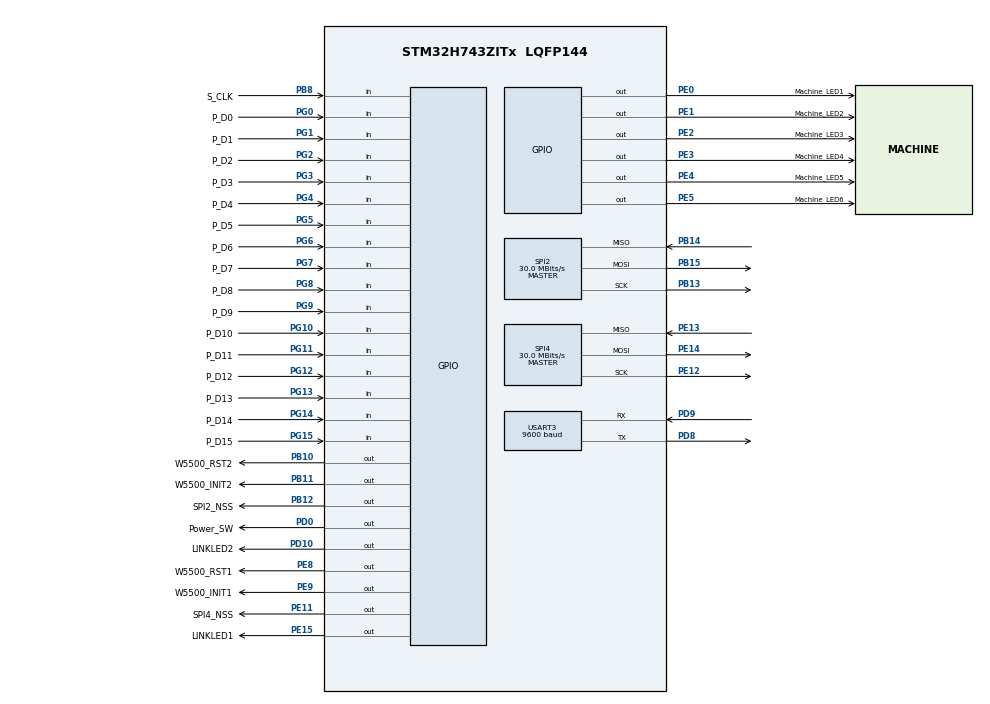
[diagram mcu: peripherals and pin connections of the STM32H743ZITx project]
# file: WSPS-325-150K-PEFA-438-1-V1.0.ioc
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Dma.Request0=USART3_RX
Dma.Request1=USART3_TX
Dma.USART3_RX.0.Direction=DMA_PERIPH_TO_MEMORY
Dma.USART3_RX.0.EventEnable=DISABLE
Dma.USART3_RX.0.FIFOMode=DMA_FIFOMODE_DISABLE
Dma.USART3_RX.0.Instance=DMA1_Stream0
Dma.USART3_RX.0.MemDataAlignment=DMA_MDATAALIGN_BYTE
Dma.USART3_RX.0.MemInc=DMA_MINC_ENABLE
Dma.USART3_RX.0.Mode=DMA_NORMAL
Dma.USART3_RX.0.PeriphDataAlignment=DMA_PDATAALIGN_BYTE
Dma.USART3_RX.0.PeriphInc=DMA_PINC_DISABLE
Dma.USART3_RX.0.Polarity=HAL_DMAMUX_REQ_GEN_RISING
Dma.USART3_RX.0.Priority=DMA_PRIORITY_LOW
Dma.USART3_RX.0.RequestNumber=1
Dma.USART3_RX.0.SignalID=NONE
Dma.USART3_RX.0.SyncEnable=DISABLE
Dma.USART3_RX.0.SyncPolarity=HAL_DMAMUX_SYNC_NO_EVENT
Dma.USART3_RX.0.SyncRequestNumber=1
Dma.USART3_RX.0.SyncSignalID=NONE
Dma.USART3_TX.1.Direction=DMA_MEMORY_TO_PERIPH
Dma.USART3_TX.1.EventEnable=DISABLE
Dma.USART3_TX.1.FIFOMode=DMA_FIFOMODE_DISABLE
Dma.USART3_TX.1.Instance=DMA1_Stream1
Dma.USART3_TX.1.MemDataAlignment=DMA_MDATAALIGN_BYTE
Dma.USART3_TX.1.MemInc=DMA_MINC_ENABLE
Dma.USART3_TX.1.Mode=DMA_NORMAL
Dma.USART3_TX.1.PeriphDataAlignment=DMA_PDATAALIGN_BYTE
Dma.USART3_TX.1.PeriphInc=DMA_PINC_DISABLE
Dma.USART3_TX.1.Polarity=HAL_DMAMUX_REQ_GEN_RISING
Dma.USART3_TX.1.Priority=DMA_PRIORITY_LOW
Dma.USART3_TX.1.RequestNumber=1
Dma.USART3_TX.1.SignalID=NONE
Dma.USART3_TX.1.SyncEnable=DISABLE
Dma.USART3_TX.1.SyncPolarity=HAL_DMAMUX_SYNC_NO_EVENT
Dma.USART3_TX.1.SyncRequestNumber=1
Dma.USART3_TX.1.SyncSignalID=NONE
Mcu.Family=STM32H7
Mcu.Name=STM32H743ZITx
Mcu.Package=LQFP144
NVIC.DMA1_Stream0_IRQn=true\:2\:0\:true\:false\:true\:false\:true
NVIC.DMA1_Stream1_IRQn=true\:2\:1\:true\:false\:true\:false\:true
NVIC.PriorityGroup=NVIC_PRIORITYGROUP_2
NVIC.USART3_IRQn=true\:0\:0\:false\:false\:true\:true\:true
PA13\ (JTMS/SWDIO).Mode=JTAG_5_pins
PA13\ (JTMS/SWDIO).Signal=DEBUG_JTMS-SWDIO
PA14\ (JTCK/SWCLK).Mode=JTAG_5_pins
PA14\ (JTCK/SWCLK).Signal=DEBUG_JTCK-SWCLK
PA15\ (JTDI).Mode=JTAG_5_pins
PA15\ (JTDI).Signal=DEBUG_JTDI
PB10.GPIO_Label=W5500_RST2
PB10.Signal=GPIO_Output
PB11.GPIO_Label=W5500_INIT2
PB11.Signal=GPIO_Output
PB12.GPIO_Label=SPI2_NSS
PB12.Signal=GPIO_Output
PB13.Mode=Full_Duplex_Master
PB13.Signal=SPI2_SCK
PB14.Mode=Full_Duplex_Master
PB14.Signal=SPI2_MISO
PB15.Mode=Full_Duplex_Master
PB15.Signal=SPI2_MOSI
PB3\ (JTDO/TRACESWO).Mode=JTAG_5_pins
PB3\ (JTDO/TRACESWO).Signal=DEBUG_JTDO-SWO
PB4\ (NJTRST).Mode=JTAG_5_pins
PB4\ (NJTRST).Signal=DEBUG_JTRST
PB8.GPIO_Label=S_CLK
PB8.Signal=GPIO_Input
PD0.GPIO_Label=Power_SW
PD0.GPIO_PuPd=GPIO_PULLUP
PD0.Signal=GPIO_Output
PD10.GPIO_Label=LINKLED2
PD10.Signal=GPIO_Output
PD8.Mode=Asynchronous
PD8.Signal=USART3_TX
PD9.Mode=Asynchronous
PD9.Signal=USART3_RX
PE0.GPIO_Label=Machine_LED1
PE0.Signal=GPIO_Output
PE1.GPIO_Label=Machine_LED2
PE1.Signal=GPIO_Output
PE11.GPIO_Label=SPI4_NSS
PE11.Signal=GPIO_Output
PE12.Mode=Full_Duplex_Master
PE12.Signal=SPI4_SCK
PE13.Mode=Full_Duplex_Master
PE13.Signal=SPI4_MISO
PE14.Mode=Full_Duplex_Master
PE14.Signal=SPI4_MOSI
PE15.GPIO_Label=LINKLED1
PE15.Signal=GPIO_Output
PE2.GPIO_Label=Machine_LED3
PE2.Signal=GPIO_Output
PE3.GPIO_Label=Machine_LED4
PE3.Signal=GPIO_Output
PE4.GPIO_Label=Machine_LED5
PE4.Signal=GPIO_Output
PE5.GPIO_Label=Machine_LED6
PE5.Signal=GPIO_Output
PE8.GPIO_Label=W5500_RST1
PE8.Signal=GPIO_Output
PE9.GPIO_Label=W5500_INIT1
PE9.Signal=GPIO_Output
PG0.GPIO_Label=P_D0
PG0.Signal=GPIO_Input
PG1.GPIO_Label=P_D1
PG1.Signal=GPIO_Input
PG10.GPIO_Label=P_D10
PG10.Signal=GPIO_Input
PG11.GPIO_Label=P_D11
PG11.Signal=GPIO_Input
PG12.GPIO_Label=P_D12
PG12.Signal=GPIO_Input
PG13.GPIO_Label=P_D13
PG13.Signal=GPIO_Input
PG14.GPIO_Label=P_D14
PG14.Signal=GPIO_Input
PG15.GPIO_Label=P_D15
PG15.Signal=GPIO_Input
PG2.GPIO_Label=P_D2
PG2.Signal=GPIO_Input
PG3.GPIO_Label=P_D3
PG3.Signal=GPIO_Input
PG4.GPIO_Label=P_D4
PG4.Signal=GPIO_Input
PG5.GPIO_Label=P_D5
PG5.Signal=GPIO_Input
PG6.GPIO_Label=P_D6
PG6.Signal=GPIO_Input
PG7.GPIO_Label=P_D7
PG7.Signal=GPIO_Input
PG8.GPIO_Label=P_D8
PG8.Signal=GPIO_Input
PG9.GPIO_Label=P_D9
PG9.Signal=GPIO_Input
PH0-OSC_IN\ (PH0).Mode=HSE-External-Clock-Source
PH0-OSC_IN\ (PH0).Signal=RCC_OSC_IN
ProjectManager.HeapSize=0x200
ProjectManager.StackSize=0x400
ProjectManager.TargetToolchain=MDK-ARM V5.32
RCC.ADCFreq_Value=120000000
RCC.APB1Freq_Value=120000000
RCC.APB2Freq_Value=120000000
RCC.APB3Freq_Value=120000000
RCC.APB4Freq_Value=120000000
RCC.CortexFreq_Value=480000000
RCC.D1PPRE=RCC_APB3_DIV2
RCC.D2PPRE1=RCC_APB1_DIV2
RCC.D2PPRE2=RCC_APB2_DIV2
RCC.D3PPRE=RCC_APB4_DIV2
RCC.DIVM1=10
RCC.DIVM2=10
RCC.DIVM3=10
RCC.DIVN1=240
RCC.DIVN2=240
RCC.DIVN3=240
RCC.DIVP2=8
RCC.DIVP3=8
RCC.DIVQ1=8
RCC.DIVQ2=8
RCC.DIVQ3=8
RCC.DIVR1=8
RCC.HCLKFreq_Value=240000000
RCC.HPRE=RCC_HCLK_DIV2
RCC.HSE_VALUE=40000000
RCC.PLLSourceVirtual=RCC_PLLSOURCE_HSE
RCC.SYSCLKFreq_VALUE=480000000
RCC.SYSCLKSource=RCC_SYSCLKSOURCE_PLLCLK
RCC.USBFreq_Value=120000000
SPI2.BaudRatePrescaler=SPI_BAUDRATEPRESCALER_4
SPI2.CLKPhase=SPI_PHASE_2EDGE
SPI2.CLKPolarity=SPI_POLARITY_HIGH
SPI2.CalculateBaudRate=30.0 MBits/s
SPI2.DataSize=SPI_DATASIZE_8BIT
SPI2.Direction=SPI_DIRECTION_2LINES
SPI2.Mode=SPI_MODE_MASTER
SPI2.NSSPMode=SPI_NSS_PULSE_DISABLE
SPI2.VirtualType=VM_MASTER
SPI4.BaudRatePrescaler=SPI_BAUDRATEPRESCALER_4
SPI4.CLKPhase=SPI_PHASE_2EDGE
SPI4.CLKPolarity=SPI_POLARITY_HIGH
SPI4.CalculateBaudRate=30.0 MBits/s
SPI4.DataSize=SPI_DATASIZE_8BIT
SPI4.Direction=SPI_DIRECTION_2LINES
SPI4.Mode=SPI_MODE_MASTER
SPI4.NSSPMode=SPI_NSS_PULSE_DISABLE
SPI4.VirtualType=VM_MASTER
USART3.BaudRate=9600
USART3.ClockPrescaler=PRESCALER_DIV1
USART3.DMADisableonRxErrorParam=ADVFEATURE_DMA_DISABLEONRXERROR
USART3.OverSampling=UART_OVERSAMPLING_8
USART3.OverrunDisableParam=ADVFEATURE_OVERRUN_DISABLE
USART3.VirtualMode-Asynchronous=VM_ASYNC
board=custom

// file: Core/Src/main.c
/* USER CODE BEGIN Header */
/**
  ******************************************************************************
  * @file           : main.c
  * @brief          : Main program body
  ******************************************************************************
  * @attention
  *
  * <h2><center>&copy; Copyright (c) 2022 STMicroelectronics.
  * All rights reserved.</center></h2>
  *
  * This software component is licensed by ST under BSD 3-Clause license,
  * the "License"; You may not use this file except in compliance with the
  * License. You may obtain a copy of the License at:
  *                        opensource.org/licenses/BSD-3-Clause
  *
  ******************************************************************************
  */
/* USER CODE END Header */
#include "main.h"
#include "dma.h"
#include "spi.h"
#include "usart.h"
#include "gpio.h"

/* USER CODE BEGIN Includes */

#include "../../App/task.h"
#include "../../App/tcp.h"
#include "../../App/udp.h"
#include "../../App/dc_rs485.h"
/* USER CODE END Includes */

void SystemClock_Config(void);

int main(void)
{

  /* MCU Configuration--------------------------------------------------------*/

  /* Reset of all peripherals, Initializes the Flash interface and the Systick. */
  HAL_Init();

  /* Configure the system clock */
  SystemClock_Config();

  /* Initialize all configured peripherals */
  MX_GPIO_Init();
  MX_SPI2_Init();
  MX_SPI4_Init();
  MX_DMA_Init();
  MX_USART3_UART_Init();
  /* USER CODE BEGIN 2 */
  Device_Init();
  /* USER CODE END 2 */

  /* Infinite loop */
  while (1)
  {

    /* USER CODE BEGIN 3 */
      Task_TCP_TOP();       /*UDP中间层对上层通信*/
      Task_UDP();       /*UDP中间层对底层通信*/
      Task_Write_Modbus();
      Task_Control();
      Task_DC_Read_Data();
      Task_Ads8411_Send_Data();
      Task_Get_Temp();
  }
  /* USER CODE END 3 */
}

void SystemClock_Config(void)
{
  RCC_OscInitTypeDef RCC_OscInitStruct = {0};
  RCC_ClkInitTypeDef RCC_ClkInitStruct = {0};

  /** Supply configuration update enable
  */
  HAL_PWREx_ConfigSupply(PWR_LDO_SUPPLY);
  /** Configure the main internal regulator output voltage
  */
  __HAL_PWR_VOLTAGESCALING_CONFIG(PWR_REGULATOR_VOLTAGE_SCALE0);

  while(!__HAL_PWR_GET_FLAG(PWR_FLAG_VOSRDY)) {}
  /** Initializes the RCC Oscillators according to the specified parameters
  * in the RCC_OscInitTypeDef structure.
  */
  RCC_OscInitStruct.OscillatorType = RCC_OSCILLATORTYPE_HSE;
  RCC_OscInitStruct.HSEState = RCC_HSE_BYPASS;
  RCC_OscInitStruct.PLL.PLLState = RCC_PLL_ON;
  RCC_OscInitStruct.PLL.PLLSource = RCC_PLLSOURCE_HSE;
  RCC_OscInitStruct.PLL.PLLM = 10;
  RCC_OscInitStruct.PLL.PLLN = 240;
  RCC_OscInitStruct.PLL.PLLP = 2;
  RCC_OscInitStruct.PLL.PLLQ = 8;
  RCC_OscInitStruct.PLL.PLLR = 8;
  RCC_OscInitStruct.PLL.PLLRGE = RCC_PLL1VCIRANGE_2;
  RCC_OscInitStruct.PLL.PLLVCOSEL = RCC_PLL1VCOWIDE;
  RCC_OscInitStruct.PLL.PLLFRACN = 0;
  if (HAL_RCC_OscConfig(&RCC_OscInitStruct) != HAL_OK)
  {
    Error_Handler();
  }
  /** Initializes the CPU, AHB and APB buses clocks
  */
  RCC_ClkInitStruct.ClockType = RCC_CLOCKTYPE_HCLK|RCC_CLOCKTYPE_SYSCLK
                              |RCC_CLOCKTYPE_PCLK1|RCC_CLOCKTYPE_PCLK2
                              |RCC_CLOCKTYPE_D3PCLK1|RCC_CLOCKTYPE_D1PCLK1;
  RCC_ClkInitStruct.SYSCLKSource = RCC_SYSCLKSOURCE_PLLCLK;
  RCC_ClkInitStruct.SYSCLKDivider = RCC_SYSCLK_DIV1;
  RCC_ClkInitStruct.AHBCLKDivider = RCC_HCLK_DIV2;
  RCC_ClkInitStruct.APB3CLKDivider = RCC_APB3_DIV2;
  RCC_ClkInitStruct.APB1CLKDivider = RCC_APB1_DIV2;
  RCC_ClkInitStruct.APB2CLKDivider = RCC_APB2_DIV2;
  RCC_ClkInitStruct.APB4CLKDivider = RCC_APB4_DIV2;

  if (HAL_RCC_ClockConfig(&RCC_ClkInitStruct, FLASH_LATENCY_4) != HAL_OK)
  {
    Error_Handler();
  }
}

void Error_Handler(void)
{
  __disable_irq();
  while (1)
  {
  }
}

/************************ (C) COPYRIGHT STMicroelectronics *****END OF FILE****/
